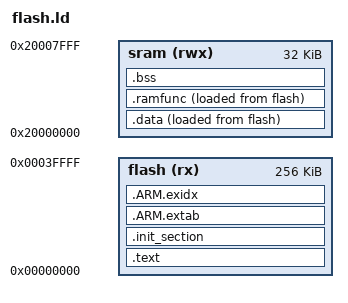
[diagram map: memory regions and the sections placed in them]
/****************************************************************************
 * boards/arm/samd2l2/switchcore/scripts/flash.ld
 ****************************************************************************/

/* The ATSAMD21J18A has 256KB of FLASH beginning at address 0x0000:0000 and
 * 32KB of SRAM beginning at address 0x2000:0000
 */

MEMORY
{
  flash (rx)  : ORIGIN = 0x00000000, LENGTH = 256K
  sram  (rwx) : ORIGIN = 0x20000000, LENGTH = 32K
}

OUTPUT_ARCH(arm)
EXTERN(_vectors)
ENTRY(_stext)

SECTIONS
{
    .text : {
        _stext = ABSOLUTE(.);
        *(.vectors)
        *(.text .text.*)
        *(.fixup)
        *(.gnu.warning)
        *(.rodata .rodata.*)
        *(.gnu.linkonce.t.*)
        *(.glue_7)
        *(.glue_7t)
        *(.got)
        *(.gcc_except_table)
        *(.gnu.linkonce.r.*)
        _etext = ABSOLUTE(.);
    } > flash

    .init_section : {
        _sinit = ABSOLUTE(.);
        KEEP(*(SORT_BY_INIT_PRIORITY(.init_array.*) SORT_BY_INIT_PRIORITY(.ctors.*)))
        KEEP(*(.init_array EXCLUDE_FILE(*crtbegin.o *crtbegin?.o *crtend.o *crtend?.o) .ctors))
        _einit = ABSOLUTE(.);
    } > flash

    .ARM.extab : {
        *(.ARM.extab*)
    } >flash

    .ARM.exidx : {
        __exidx_start = ABSOLUTE(.);
        *(.ARM.exidx*)
        __exidx_end = ABSOLUTE(.);
    } >flash

    .data : {
        _sdata = ABSOLUTE(.);
        *(.data .data.*)
        *(.gnu.linkonce.d.*)
        CONSTRUCTORS
        . = ALIGN(4);
        _edata = ABSOLUTE(.);
    } > sram AT > flash

    _eronly = LOADADDR(.data);

    .ramfunc ALIGN(4): {
        _sramfuncs = ABSOLUTE(.);
        *(.ramfunc  .ramfunc.*)
        _eramfuncs = ABSOLUTE(.);
    } > sram AT > flash

    _framfuncs = LOADADDR(.ramfunc);

    .bss : {
        _sbss = ABSOLUTE(.);
        *(.bss .bss.*)
        *(.gnu.linkonce.b.*)
        *(COMMON)
        . = ALIGN(4);
        _ebss = ABSOLUTE(.);
    } > sram

    /* Stabs debugging sections. */
    .stab 0 : { *(.stab) }
    .stabstr 0 : { *(.stabstr) }
    .stab.excl 0 : { *(.stab.excl) }
    .stab.exclstr 0 : { *(.stab.exclstr) }
    .stab.index 0 : { *(.stab.index) }
    .stab.indexstr 0 : { *(.stab.indexstr) }
    .comment 0 : { *(.comment) }
    .debug_abbrev 0 : { *(.debug_abbrev) }
    .debug_info 0 : { *(.debug_info) }
    .debug_line 0 : { *(.debug_line) }
    .debug_pubnames 0 : { *(.debug_pubnames) }
    .debug_aranges 0 : { *(.debug_aranges) }
}
